# CH32V00Xxx register map
Vendor: WCH Ltd.; File version: 1.0
CH32V00Xxx View File
Registers are 32-bit, read-write, reset 0x0 unless marked. A register's access mark holds for its fields unless they carry their own. Offsets are from the block's base; lines under a group give offsets from that group; [hi:lo] are bit positions; {n}, {i} and the like mark numbered series; 'fields as' and 'values as' point back to an identical list; <NAME> marks a mode.

## Memory map
0x1FFFF7E0 ESIG size 0x14 — Device electronic signature
0x40000000 TIM2 size 0x400 — General purpose timer
0x40000800 TIM3 size 0x400 — General reduced timer
0x40002C00 WWDG size 0x400 — Window watchdog
0x40003000 IWDG size 0x400 — Independent watchdog
0x40004400 USART2 size 0x400
0x40005400 I2C1 size 0x400 — Inter integrated circuit
0x40007000 PWR size 0x400 — Power control
0x40010000 AFIO size 0x400 — Alternate function I/O
0x40010400 EXTI size 0x400
0x40010800 GPIOA size 0x400 — General purpose I/O
0x40010C00 GPIOB size 0x400
0x40011000 GPIOC size 0x400
0x40011400 GPIOD size 0x400
0x40012400 ADC_TKEY size 0x400 — Analog to digital converter
0x40012C00 TIM1 size 0x400 — Advanced timer
0x40013000 SPI1 size 0x400 — Serial peripheral interface
0x40013800 USART1 size 0x400 — Universal synchronous asynchronous receiver transmitter
0x40020000 DMA1 size 0x400 — DMA1 controller
0x40021000 RCC size 0x400 — Reset and clock control
0x40022000 FLASH size 0x400
0x40023800 EXTEN size 0x400 — Extend configuration
0x40024000 OPA size 0x400 — OPA and CMP
0xE000E000 PFIC size 0x1100 — Programmable Fast Interrupt Controller

## Interrupts
16 WWDG — Window Watchdog interrupt
17 PVD (PWR) — PVD through EXTI line detection interrupt
18 FLASH — Flash global interrupt
19 RCC — Reset and clock control interrupt
20 EXTI7_0 (EXTI) — EXTI Line[7:0] interrupt
21 AWU (PWR) — AWU global interrupt
22 DMA1_Channel1 (DMA1) — DMA1 Channel 1 global interrupt
23 DMA1_Channel2 (DMA1) — DMA1 Channel 2 global interrupt
24 DMA1_Channel3 (DMA1) — DMA1 Channel 3 global interrupt
25 DMA1_Channel4 (DMA1) — DMA1 Channel 4 global interrupt
26 DMA1_Channel5 (DMA1) — DMA1 Channel 5 global interrupt
27 DMA1_Channel6 (DMA1) — DMA1 Channel 6 global interrupt
28 DMA1_Channel7 (DMA1) — DMA1 Channel 7 global interrupt
29 ADC (ADC_TKEY) — ADC global interrupt
30 I2C1_EV (I2C1) — I2C1 event interrupt
31 I2C1_ER (I2C1) — I2C1 error interrupt
32 USART1 — USART1 global interrupt
33 SPI1 — SPI1 global interrupt
34 TIM1BRK (TIM1) — TIM1 Break interrupt
35 TIM1UP (TIM1) — TIM1 Update interrupt
36 TIM1RG (TIM1) — TIM1 Trigger and Commutation interrupts
37 TIM1CC (TIM1) — TIM1 Capture Compare interrupt
38 TIM2 — TIM2 global interrupt
39 USART2 — USART2 global interrupt
40 OPCM (OPA) — OPA and CMP global interrupt

## PWR — Power control
Base 0x40007000
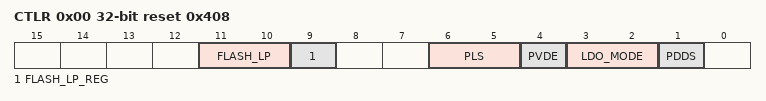
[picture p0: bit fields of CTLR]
0x00 CTLR reset 0x408 — Power control register (PWR_CTRL)
  [11:10] FLASH_LP — LP Config
  [9] FLASH_LP_REG — LP_REG enable
  [6:5] PLS — PVD Level Selection
  [4] PVDE — Power Voltage Detector Enable
  [3:2] LDO_MODE — LDO work mode Selection
  [1] PDDS — Power Down Deep Sleep
0x04 CSR ro — Power control state register (PWR_CSR)
  [2] PVDO — PVD Output
0x08 AWUCSR — Automatic wake-up control state register (PWR_AWUCSR)
  [1] AWUEN — Automatic wake-up enable
0x0C AWUWR reset 0x3F — Automatic wake window comparison value register (PWR_AWUWR)
  [5:0] AWUWR — AWU window value
0x10 AWUPSC — Automatic wake-up prescaler register (PWR_AWUPSC)
  [3:0] AWUPSC — Wake-up prescaler

## EXTEN — Extend configuration
Base 0x40023800
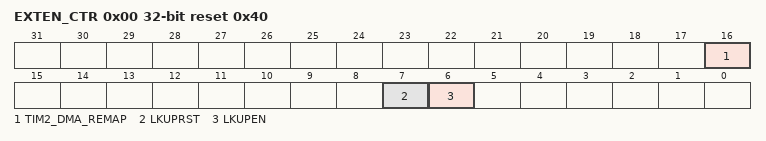
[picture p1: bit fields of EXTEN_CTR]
0x00 EXTEN_CTR access per field reset 0x40 — Configure the extended control register
  [16] TIM2_DMA_REMAP rw — TIN2 DMA multiplexing
  [7] LKUPRST read/clear — LOCKUP RESET
  [6] LKUPEN rw — LOCKUP_Enable

## GPIOA — General purpose I/O
Base 0x40010800
Same registers: GPIOB 0x40010C00, GPIOC 0x40011000, GPIOD 0x40011400
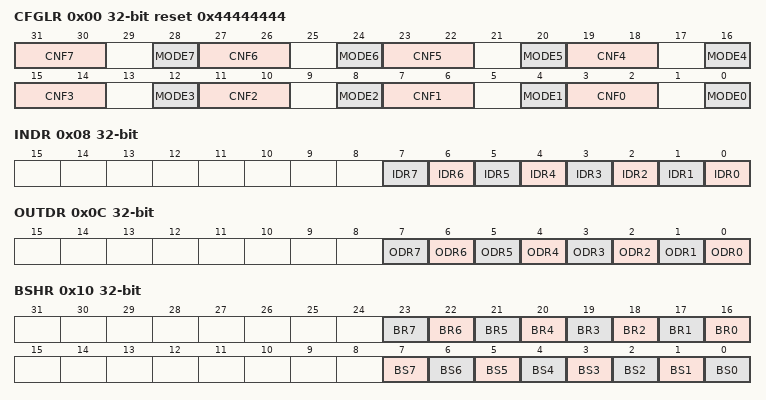
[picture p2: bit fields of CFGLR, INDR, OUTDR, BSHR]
0x00 CFGLR reset 0x44444444 — Port configuration register low (GPIOn_CFGLR)
  [31:30] CNF7 — Port n.7 configuration bits
  [28] MODE7 — Port n.7 mode bits
  [27:26] CNF6 — Port n.6 configuration bits
  [24] MODE6 — Port n.6 mode bits
  [23:22] CNF5 — Port n.5 configuration bits
  [20] MODE5 — Port n.5 mode bits
  [19:18] CNF4 — Port n.4 configuration bits
  [16] MODE4 — Port n.4 mode bits
  [15:14] CNF3 — Port n.3 configuration bits
  [12] MODE3 — Port n.3 mode bits
  [11:10] CNF2 — Port n.2 configuration bits
  [8] MODE2 — Port n.2 mode bits
  [7:6] CNF1 — Port n.1 configuration bits
  [4] MODE1 — Port n.1 mode bits
  [3:2] CNF0 — Port n.0 configuration bits
  [0] MODE0 — Port n.0 mode bits
0x08 INDR ro — Port input data register (GPIOn_INDR)
  [n] IDR{n} (n=0..7) — Port input data
0x0C OUTDR — Port output data register (GPIOn_OUTDR)
  [n] ODR{n} (n=0..7) — Port output data
0x10 BSHR wo — Port bit set/reset register (GPIOn_BSHR)
  [n+16] BR{n} (n=0..7) — Reset bit {n}
  [n] BS{n} (n=3..7) — Set bit {n}
  [2] BS2 — Set bit 1
  [1] BS1 — Set bit 1
  [0] BS0 — Set bit 0
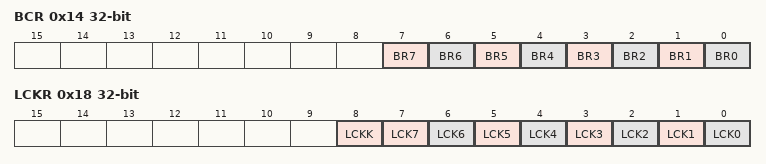
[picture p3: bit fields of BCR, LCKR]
0x14 BCR wo — Port bit reset register (GPIOn_BCR)
  [n] BR{n} (n=3..7) — Reset bit {n}
  [2] BR2 — Reset bit 1
  [1] BR1 — Reset bit 1
  [0] BR0 — Reset bit 0
0x18 LCKR — Port configuration lock register
  [8] LCKK — Lock key
  [n] LCK{n} (n=0..7) — Port A Lock bit {n}
